# STM32F205 register map
File version: 1.0
CPU: CM3 r1p1, little endian, no MPU, no FPU, 4 interrupt priority bits
Registers are 32-bit, read-write, reset 0x0 unless marked. A register's access mark holds for its fields unless they carry their own. Offsets are from the block's base; [hi:lo] are bit positions; {n}, {i} and the like mark numbered series.

## GPIOI — General-purpose I/Os
Base 0x40022000
Same registers: GPIOC 0x40020800, GPIOD 0x40020C00, GPIOE 0x40021000, GPIOF 0x40021400, GPIOG 0x40021800, GPIOH 0x40021C00
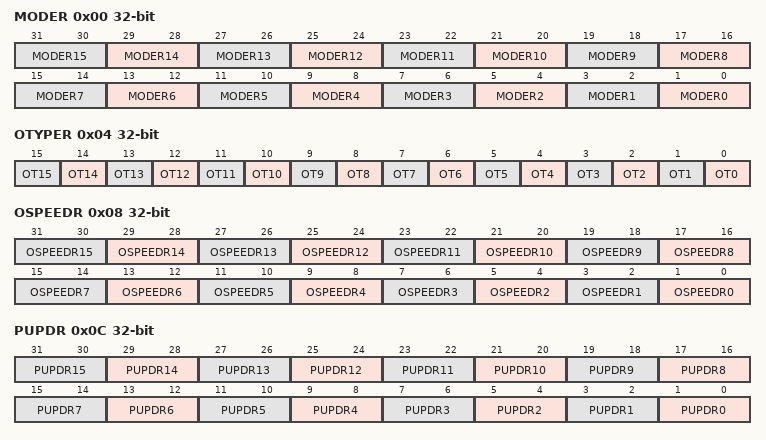
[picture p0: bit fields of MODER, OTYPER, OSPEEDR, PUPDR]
0x00 MODER — GPIO port mode register
  [2n+1:2n] MODER{n} (n=0..15) — Port x configuration bits (y = 0..15)
0x04 OTYPER — GPIO port output type register
  [n] OT{n} (n=0..15) — Port x configuration bit {n}
0x08 OSPEEDR — GPIO port output speed register
  [2n+1:2n] OSPEEDR{n} (n=0..15) — Port x configuration bits (y = 0..15)
0x0C PUPDR — GPIO port pull-up/pull-down register
  [2n+1:2n] PUPDR{n} (n=0..15) — Port x configuration bits (y = 0..15)
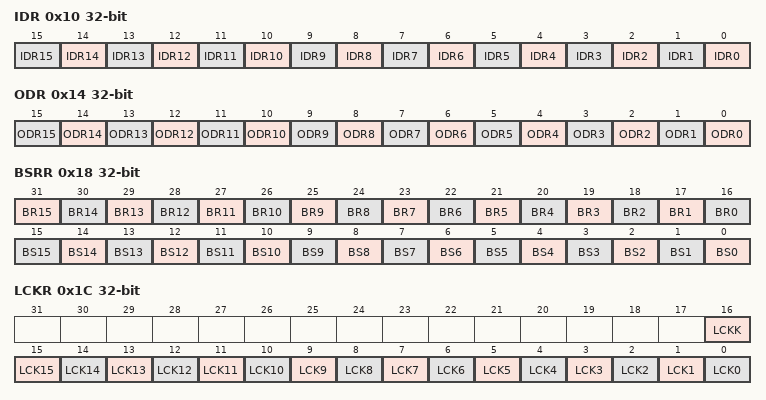
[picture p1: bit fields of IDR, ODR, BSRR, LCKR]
0x10 IDR ro — GPIO port input data register
  [n] IDR{n} (n=0..15) — Port input data (y = 0..15)
0x14 ODR — GPIO port output data register
  [n] ODR{n} (n=0..15) — Port output data (y = 0..15)
0x18 BSRR wo — GPIO port bit set/reset register
  [n+16] BR{n} (n=1..15) — Port x reset bit y (y = 0..15)
  [16] BR0 — Port x set bit y (y= 0..15)
  [n] BS{n} (n=0..15) — Port x set bit y (y= 0..15)
0x1C LCKR — GPIO port configuration lock register
  [16] LCKK — Port x lock bit y (y= 0..15)
  [n] LCK{n} (n=0..15) — Port x lock bit y (y= 0..15)
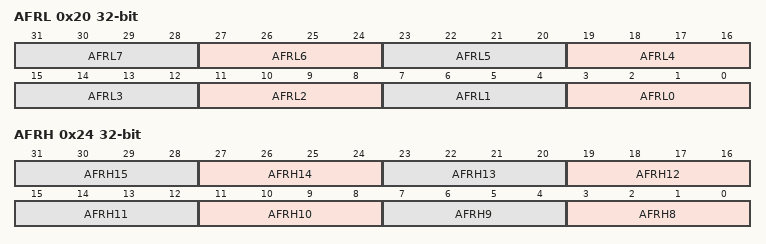
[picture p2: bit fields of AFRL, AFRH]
0x20 AFRL — GPIO alternate function low register
  [4n+3:4n] AFRL{n} (n=0..7) — Alternate function selection for port x bit y (y = 0..7)
0x24 AFRH — GPIO alternate function high register
  [4n-29:4n-32] AFRH{n} (n=8..15) — Alternate function selection for port x bit y (y = 8..15)

## GPIOB — General-purpose I/Os
Base 0x40020400
Registers as GPIOI; these are added or differ:
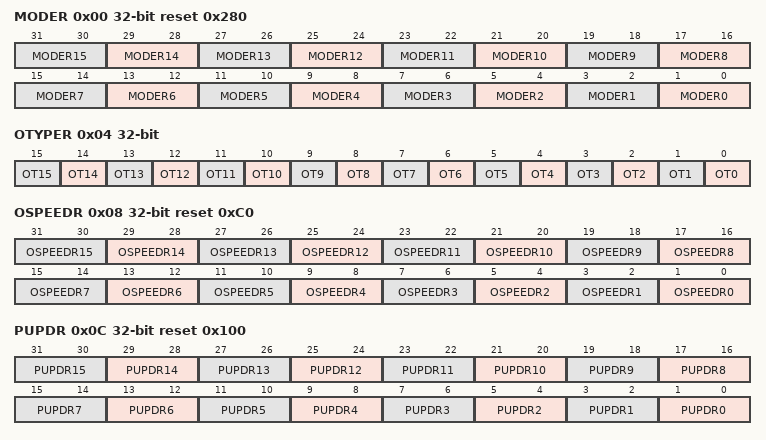
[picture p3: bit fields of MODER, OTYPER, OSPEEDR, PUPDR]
0x00 MODER reset 0x280 — GPIO port mode register
  [2n+1:2n] MODER{n} (n=0..15) — Port x configuration bits (y = 0..15)
0x04 OTYPER — GPIO port output type register
  [n] OT{n} (n=0..15) — Port x configuration bits (y = 0..15)
0x08 OSPEEDR reset 0xC0 — GPIO port output speed register
  [2n+1:2n] OSPEEDR{n} (n=0..15) — Port x configuration bits (y = 0..15)
0x0C PUPDR reset 0x100 — GPIO port pull-up/pull-down register
  [2n+1:2n] PUPDR{n} (n=0..15) — Port x configuration bits (y = 0..15)

## GPIOA — General-purpose I/Os
Base 0x40020000
Registers as GPIOI; these are added or differ:
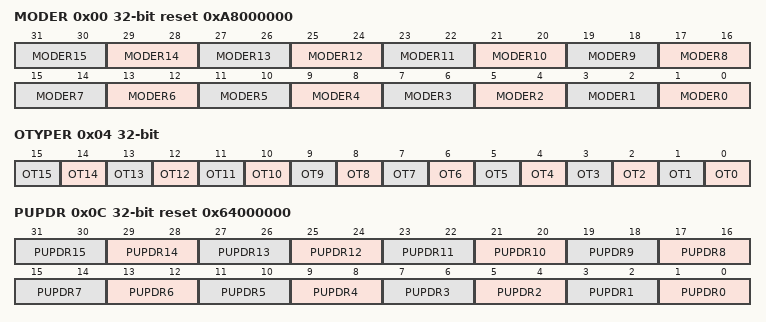
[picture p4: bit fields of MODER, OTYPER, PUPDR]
0x00 MODER reset 0xA8000000 — GPIO port mode register
  [2n+1:2n] MODER{n} (n=0..15) — Port x configuration bits (y = 0..15)
0x04 OTYPER — GPIO port output type register
  [n] OT{n} (n=0..15) — Port x configuration bits (y = 0..15)
0x0C PUPDR reset 0x64000000 — GPIO port pull-up/pull-down register
  [2n+1:2n] PUPDR{n} (n=0..15) — Port x configuration bits (y = 0..15)

## SYSCFG — System configuration controller
Base 0x40013800
0x00 MEMRM — memory remap register
  [1:0] MEM_MODE
0x04 PMC — peripheral mode configuration register
  [23] MII_RMII_SEL — Ethernet PHY interface selection
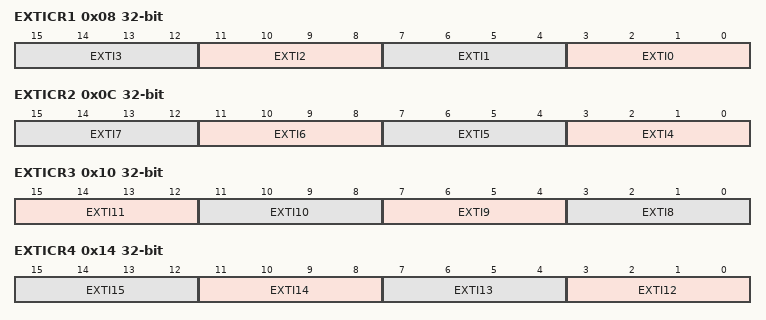
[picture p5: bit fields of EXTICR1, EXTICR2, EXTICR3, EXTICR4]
0x08 EXTICR1 — external interrupt configuration register 1
  [4n+3:4n] EXTI{n} (n=0..3) — EXTI x configuration (x = 0 to 3)
0x0C EXTICR2 — external interrupt configuration register 2
  [4n-13:4n-16] EXTI{n} (n=4..7) — EXTI x configuration (x = 4 to 7)
0x10 EXTICR3 — external interrupt configuration register 3
  [15:12] EXTI11 — EXTI x configuration (x = 8 to 11)
  [11:8] EXTI10
  [7:4] EXTI9 — EXTI x configuration (x = 8 to 11)
  [3:0] EXTI8 — EXTI x configuration (x = 8 to 11)
0x14 EXTICR4 — external interrupt configuration register 4
  [4n-45:4n-48] EXTI{n} (n=12..15) — EXTI x configuration (x = 12 to 15)
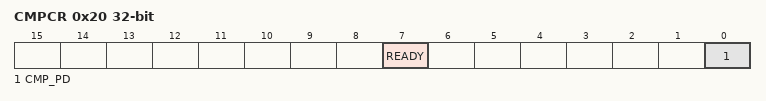
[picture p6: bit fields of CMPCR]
0x20 CMPCR access per field — Compensation cell control register
  [7] READY ro
  [0] CMP_PD rw — Compensation cell power-down

## SPI1 — Serial peripheral interface
Base 0x40013000
Same registers: SPI2 0x40003800, SPI3 0x40003C00
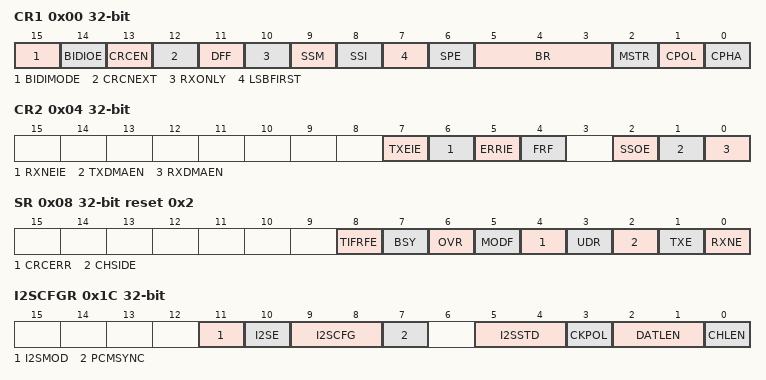
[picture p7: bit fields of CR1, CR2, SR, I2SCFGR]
0x00 CR1 — control register 1
  [15] BIDIMODE — Bidirectional data mode enable
  [14] BIDIOE — Output enable in bidirectional mode
  [13] CRCEN — Hardware CRC calculation enable
  [12] CRCNEXT — CRC transfer next
  [11] DFF — Data frame format
  [10] RXONLY — Receive only
  [9] SSM — Software slave management
  [8] SSI — Internal slave select
  [7] LSBFIRST — Frame format
  [6] SPE — SPI enable
  [5:3] BR — Baud rate control
  [2] MSTR — Master selection
  [1] CPOL — Clock polarity
  [0] CPHA — Clock phase
0x04 CR2 — control register 2
  [7] TXEIE — Tx buffer empty interrupt enable
  [6] RXNEIE — RX buffer not empty interrupt enable
  [5] ERRIE — Error interrupt enable
  [4] FRF — Frame format
  [2] SSOE — SS output enable
  [1] TXDMAEN — Tx buffer DMA enable
  [0] RXDMAEN — Rx buffer DMA enable
0x08 SR access per field reset 0x2 — status register
  [8] TIFRFE ro — TI frame format error
  [7] BSY ro — Busy flag
  [6] OVR ro — Overrun flag
  [5] MODF ro — Mode fault
  [4] CRCERR rw — CRC error flag
  [3] UDR ro — Underrun flag
  [2] CHSIDE ro — Channel side
  [1] TXE ro — Transmit buffer empty
  [0] RXNE ro — Receive buffer not empty
0x0C DR — data register
  [15:0] DR — Data register
0x10 CRCPR reset 0x7 — CRC polynomial register
  [15:0] CRCPOLY
0x14 RXCRCR ro — RX CRC register
  [15:0] RxCRC
0x18 TXCRCR ro — TX CRC register
  [15:0] TxCRC
0x1C I2SCFGR — I2S configuration register
  [11] I2SMOD — I2S mode selection
  [10] I2SE — I2S Enable
  [9:8] I2SCFG — I2S configuration mode
  [7] PCMSYNC — PCM frame synchronization
  [5:4] I2SSTD — I2S standard selection
  [3] CKPOL — Steady state clock polarity
  [2:1] DATLEN — Data length to be transferred
  [0] CHLEN — Channel length (number of bits per audio channel)
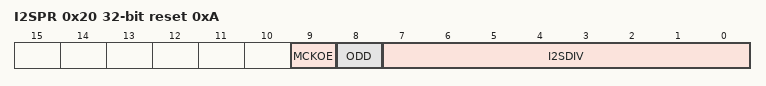
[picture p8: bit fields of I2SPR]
0x20 I2SPR reset 0xA — I2S prescaler register
  [9] MCKOE — Master clock output enable
  [8] ODD — Odd factor for the prescaler
  [7:0] I2SDIV — I2S Linear prescaler
